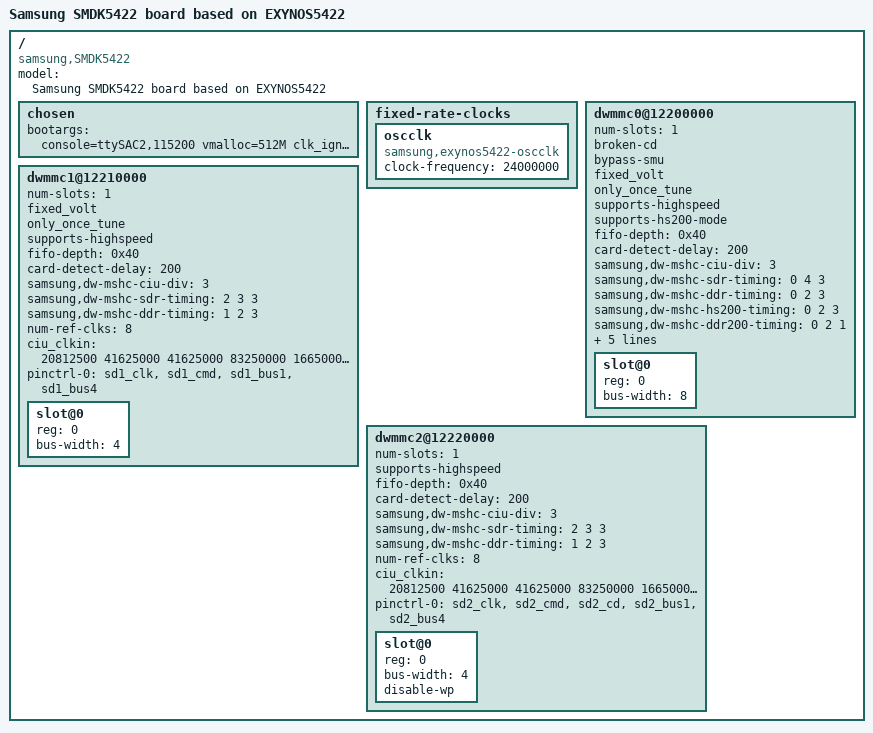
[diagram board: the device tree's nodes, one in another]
/*
 * SAMSUNG SMDK5422 board device tree source
 *
 * Copyright (c) 2013 Samsung Electronics Co., Ltd.
 *             http://www.samsung.com
 *
 * This program is free software; you can redistribute it and/or modify
 * it under the terms of the GNU General Public License version 2 as
 * published by the Free Software Foundation.
*/

/dts-v1/;
#include "exynos5422.dtsi"

/ {
	model = "Samsung SMDK5422 board based on EXYNOS5422";
	compatible = "samsung,SMDK5422", "samsung,exynos5422";

	chosen {
		bootargs = "console=ttySAC2,115200 vmalloc=512M clk_ignore_unused";
	};

	fixed-rate-clocks {
		oscclk {
			compatible = "samsung,exynos5422-oscclk";
			clock-frequency = <24000000>;
		};
	};

	dwmmc0@12200000 {
		status = "okay";
		num-slots = <1>;
		broken-cd;
		bypass-smu;
		fixed_volt;
		only_once_tune;
		supports-highspeed;
		supports-hs200-mode;
		fifo-depth = <0x40>;
		card-detect-delay = <200>;
		samsung,dw-mshc-ciu-div = <3>;
		samsung,dw-mshc-sdr-timing = <0 4 3>;
		samsung,dw-mshc-ddr-timing = <0 2 3>;
		samsung,dw-mshc-hs200-timing = <0 2 3>;
		samsung,dw-mshc-ddr200-timing = <0 2 1>;
		num-ref-clks = <8>;
		ciu_clkin = <20812500 41625000 41625000 83250000 166500000 83250000 166500000 333000000>;
		pinctrl-names = "default";
		pinctrl-0 = <&sd0_clk &sd0_cmd &sd0_rdqs &sd0_bus1 &sd0_bus4 &sd0_bus8>;

		slot@0 {
			reg = <0>;
			bus-width = <8>;
		};
	};

	dwmmc1@12210000 {
		status = "okay";
		num-slots = <1>;
		fixed_volt;
		only_once_tune;
		supports-highspeed;
		fifo-depth = <0x40>;
		card-detect-delay = <200>;
		samsung,dw-mshc-ciu-div = <3>;
		samsung,dw-mshc-sdr-timing = <2 3 3>;
		samsung,dw-mshc-ddr-timing = <1 2 3>;
		num-ref-clks = <8>;
		ciu_clkin = <20812500 41625000 41625000 83250000 166500000 83250000 166500000 333000000>;
		pinctrl-names = "default";
		pinctrl-0 = <&sd1_clk &sd1_cmd &sd1_bus1 &sd1_bus4>;

		slot@0 {
			reg = <0>;
			bus-width = <4>;
		};
	};


	dwmmc2@12220000 {
		status = "okay";
		num-slots = <1>;
		supports-highspeed;
		fifo-depth = <0x40>;
		card-detect-delay = <200>;
		samsung,dw-mshc-ciu-div = <3>;
		samsung,dw-mshc-sdr-timing = <2 3 3>;
		samsung,dw-mshc-ddr-timing = <1 2 3>;
		num-ref-clks = <8>;
		ciu_clkin = <20812500 41625000 41625000 83250000 166500000 83250000 166500000 333000000>;
		pinctrl-names = "default";
		pinctrl-0 = <&sd2_clk &sd2_cmd &sd2_cd &sd2_bus1 &sd2_bus4>;

		slot@0 {
			reg = <0>;
			bus-width = <4>;
			disable-wp;
		};
	};

};
